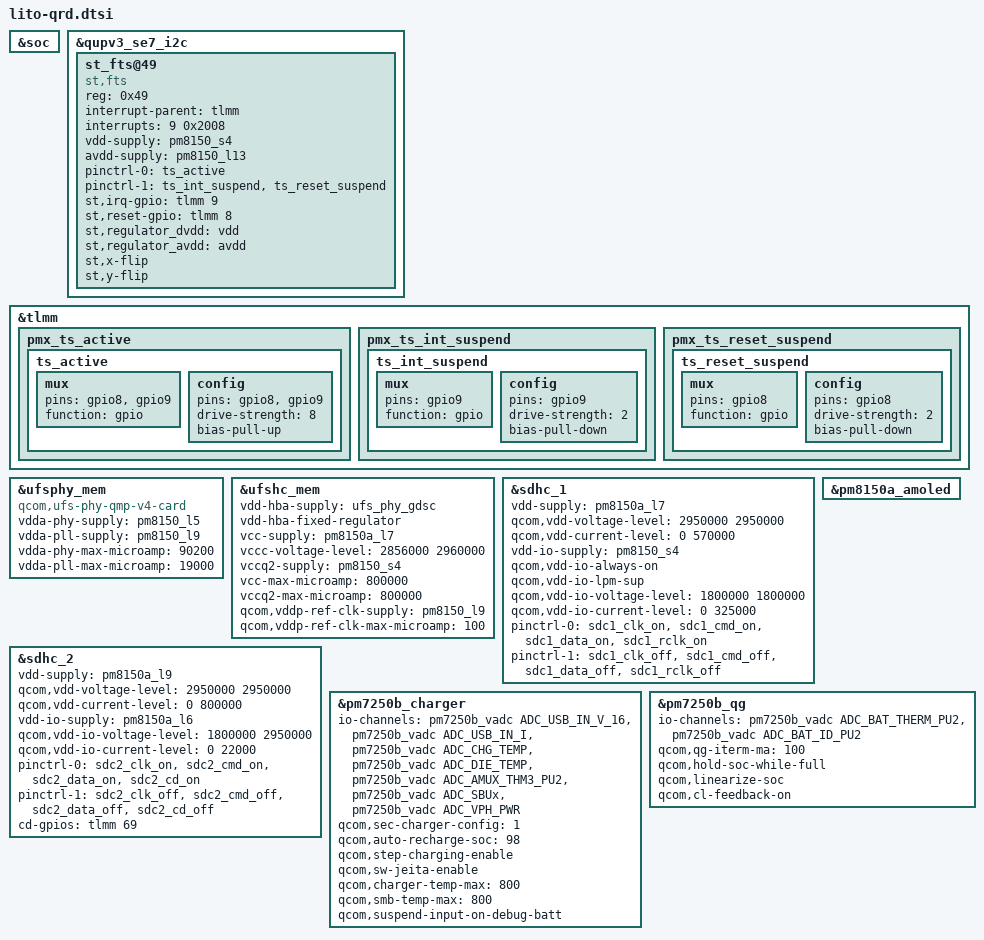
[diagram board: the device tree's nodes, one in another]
#include "lito-pmic-overlay.dtsi"
#include <dt-bindings/gpio/gpio.h>

&soc {

};

&qupv3_se7_i2c {
	#address-cells = <1>;
	#size-cells = <0>;

	status = "ok";

	st_fts@49 {
		compatible = "st,fts";
		reg = <0x49>;
		interrupt-parent = <&tlmm>;
		interrupts = <9 0x2008>;
		vdd-supply = <&pm8150_s4>;
		avdd-supply = <&pm8150_l13>;
		pinctrl-names = "pmx_ts_active", "pmx_ts_suspend";
		pinctrl-0 = <&ts_active>;
		pinctrl-1 = <&ts_int_suspend &ts_reset_suspend>;
		st,irq-gpio = <&tlmm 9 0x2008>;
		st,reset-gpio = <&tlmm 8 0x00>;
		st,regulator_dvdd = "vdd";
		st,regulator_avdd = "avdd";
		st,x-flip;
		st,y-flip;
	};
};

&tlmm {
	pmx_ts_active {
		ts_active: ts_active {
			mux {
				pins = "gpio8", "gpio9";
				function = "gpio";
			};

			config {
				pins = "gpio8", "gpio9";
				drive-strength = <8>;
				bias-pull-up;
			};
		};
	};

	pmx_ts_int_suspend {
		ts_int_suspend: ts_int_suspend {
			mux {
				pins = "gpio9";
				function = "gpio";
			};

			config {
				pins = "gpio9";
				drive-strength = <2>;
				bias-pull-down;
			};
		};
	};

	pmx_ts_reset_suspend {
		ts_reset_suspend: ts_reset_suspend {
			mux {
				pins = "gpio8";
				function = "gpio";
			};

			config {
				pins = "gpio8";
				drive-strength = <2>;
				bias-pull-down;
			};
		};
	};

};

&ufsphy_mem {
	compatible = "qcom,ufs-phy-qmp-v4-card";

	vdda-phy-supply = <&pm8150_l5>;
	vdda-pll-supply = <&pm8150_l9>;
	vdda-phy-max-microamp = <90200>;
	vdda-pll-max-microamp = <19000>;

	status = "ok";
};

&ufshc_mem {
	vdd-hba-supply = <&ufs_phy_gdsc>;
	vdd-hba-fixed-regulator;
	vcc-supply = <&pm8150a_l7>;
	vccc-voltage-level = <2856000 2960000>;
	vccq2-supply = <&pm8150_s4>;
	vcc-max-microamp = <800000>;
	vccq2-max-microamp = <800000>;

	qcom,vddp-ref-clk-supply = <&pm8150_l9>;
	qcom,vddp-ref-clk-max-microamp = <100>;

	status = "ok";
};

&sdhc_1 {
	vdd-supply = <&pm8150a_l7>;
	qcom,vdd-voltage-level = <2950000 2950000>;
	qcom,vdd-current-level = <0 570000>;

	vdd-io-supply = <&pm8150_s4>;
	qcom,vdd-io-always-on;
	qcom,vdd-io-lpm-sup;
	qcom,vdd-io-voltage-level = <1800000 1800000>;
	qcom,vdd-io-current-level = <0 325000>;

	pinctrl-names = "active", "sleep";
	pinctrl-0 = <&sdc1_clk_on &sdc1_cmd_on &sdc1_data_on
					&sdc1_rclk_on>;
	pinctrl-1 = <&sdc1_clk_off &sdc1_cmd_off &sdc1_data_off
					&sdc1_rclk_off>;

	status = "ok";
};

&sdhc_2 {
	vdd-supply = <&pm8150a_l9>;
	qcom,vdd-voltage-level = <2950000 2950000>;
	qcom,vdd-current-level = <0 800000>;

	vdd-io-supply = <&pm8150a_l6>;
	qcom,vdd-io-voltage-level = <1800000 2950000>;
	qcom,vdd-io-current-level = <0 22000>;

	pinctrl-names = "active", "sleep";
	pinctrl-0 = <&sdc2_clk_on  &sdc2_cmd_on &sdc2_data_on &sdc2_cd_on>;
	pinctrl-1 = <&sdc2_clk_off &sdc2_cmd_off &sdc2_data_off &sdc2_cd_off>;

	cd-gpios = <&tlmm 69 GPIO_ACTIVE_HIGH>;

	status = "ok";
};

&pm8150a_amoled {
	status = "ok";
};

&pm7250b_charger {
	status = "ok";
	io-channels = <&pm7250b_vadc ADC_USB_IN_V_16>,
		      <&pm7250b_vadc ADC_USB_IN_I>,
		      <&pm7250b_vadc ADC_CHG_TEMP>,
		      <&pm7250b_vadc ADC_DIE_TEMP>,
		      <&pm7250b_vadc ADC_AMUX_THM3_PU2>,
		      <&pm7250b_vadc ADC_SBUx>,
		      <&pm7250b_vadc ADC_VPH_PWR>;
	io-channel-names = "usb_in_voltage",
			   "usb_in_current",
			   "chg_temp",
			   "die_temp",
			   "conn_temp",
			   "sbux_res",
			   "vph_voltage";
	qcom,sec-charger-config = <1>;
	qcom,auto-recharge-soc = <98>;
	qcom,step-charging-enable;
	qcom,sw-jeita-enable;
	qcom,charger-temp-max = <800>;
	qcom,smb-temp-max = <800>;
	qcom,suspend-input-on-debug-batt;
};

&pm7250b_qg {
	status = "ok";
	io-channels = <&pm7250b_vadc ADC_BAT_THERM_PU2>,
		      <&pm7250b_vadc ADC_BAT_ID_PU2>;
	io-channel-names = "batt-therm",
			   "batt-id";
	qcom,qg-iterm-ma = <100>;
	qcom,hold-soc-while-full;
	qcom,linearize-soc;
	qcom,cl-feedback-on;
};
